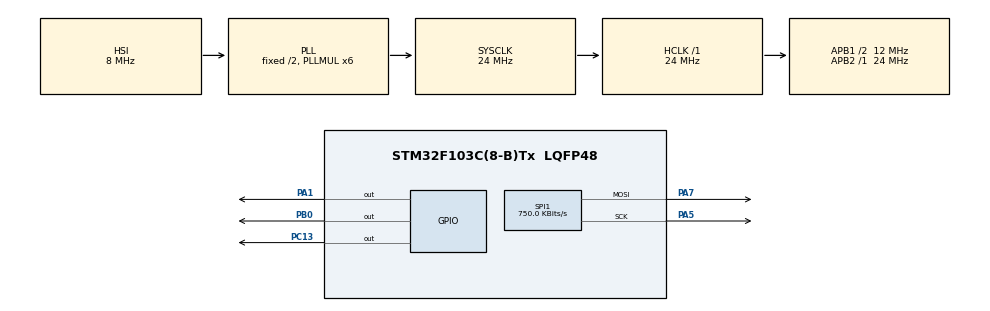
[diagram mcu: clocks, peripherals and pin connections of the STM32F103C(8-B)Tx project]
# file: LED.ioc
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Mcu.Family=STM32F1
Mcu.Name=STM32F103C(8-B)Tx
Mcu.Package=LQFP48
NVIC.PriorityGroup=NVIC_PRIORITYGROUP_4
PA1.GPIO_PuPd=GPIO_PULLUP
PA1.Signal=GPIO_Output
PA13.Mode=Serial_Wire
PA13.Signal=SYS_JTMS-SWDIO
PA14.Mode=Serial_Wire
PA14.Signal=SYS_JTCK-SWCLK
PA5.Mode=TX_Only_Simplex_Unidirect_Master
PA5.Signal=SPI1_SCK
PA7.Mode=TX_Only_Simplex_Unidirect_Master
PA7.Signal=SPI1_MOSI
PB0.Signal=GPIO_Output
PC13-TAMPER-RTC.Signal=GPIO_Output
PD0-OSC_IN.Mode=HSE-External-Oscillator
PD0-OSC_IN.Signal=RCC_OSC_IN
PD1-OSC_OUT.Mode=HSE-External-Oscillator
PD1-OSC_OUT.Signal=RCC_OSC_OUT
ProjectManager.HeapSize=0x200
ProjectManager.StackSize=0x400
ProjectManager.TargetToolchain=MDK-ARM V5.32
RCC.AHBFreq_Value=24000000
RCC.APB1CLKDivider=RCC_HCLK_DIV2
RCC.APB1Freq_Value=12000000
RCC.APB1TimFreq_Value=24000000
RCC.APB2Freq_Value=24000000
RCC.APB2TimFreq_Value=24000000
RCC.HCLKFreq_Value=24000000
RCC.PLLMUL=RCC_PLL_MUL6
RCC.SYSCLKFreq_VALUE=24000000
RCC.SYSCLKSource=RCC_SYSCLKSOURCE_PLLCLK
RCC.USBFreq_Value=24000000
SPI1.BaudRatePrescaler=SPI_BAUDRATEPRESCALER_32
SPI1.CalculateBaudRate=750.0 KBits/s
SPI1.Direction=SPI_DIRECTION_2LINES
SPI1.Mode=SPI_MODE_MASTER
SPI1.VirtualType=VM_MASTER
board=custom

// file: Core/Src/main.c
/* USER CODE BEGIN Header */
/**
  ******************************************************************************
  * @file           : main.c
  * @brief          : Main program body
  ******************************************************************************
  * @attention
  *
  * Copyright (c) 2026 STMicroelectronics.
  * All rights reserved.
  *
  * This software is licensed under terms that can be found in the LICENSE file
  * in the root directory of this software component.
  * If no LICENSE file comes with this software, it is provided AS-IS.
  *
  ******************************************************************************
  */
/* USER CODE END Header */
#include "main.h"

SPI_HandleTypeDef hspi1;

void SystemClock_Config(void);
static void MX_GPIO_Init(void);
static void MX_SPI1_Init(void);

/* USER CODE BEGIN 0 */
void writeDataSPI(uint8_t data)
{
	HAL_GPIO_WritePin(GPIOB, GPIO_PIN_0,0);
	HAL_SPI_Transmit(&hspi1, &data,1,1000);
	HAL_GPIO_WritePin(GPIOB, GPIO_PIN_0,1);
}
/* USER CODE END 0 */

int main(void)
{

  /* MCU Configuration--------------------------------------------------------*/

  /* Reset of all peripherals, Initializes the Flash interface and the Systick. */
  HAL_Init();

  /* Configure the system clock */
  SystemClock_Config();

  /* USER CODE BEGIN SysInit */
  // Test
  /* USER CODE END SysInit */

  /* Initialize all configured peripherals */
  MX_GPIO_Init();
  MX_SPI1_Init();
  /* USER CODE BEGIN 2 */
// 1. T?t LED tru?c khi b?t d?u (Gi? s? PC13, m?c cao l� t?t)
//HAL_GPIO_WritePin(GPIOC, GPIO_PIN_13, GPIO_PIN_SET);
//HAL_Delay(500);

// 2. Ki?m tra xem MPU c� t?n t?i tr�n chip n�y kh�ng
//if (MPU_TYPE == 0) {
//    // N?u chip kh�ng c� MPU, LED s? s�ng m�i d? b�o l?i
//    HAL_GPIO_WritePin(GPIOC, GPIO_PIN_13, GPIO_PIN_RESET);
//}

// 3. Kh?i t?o MPU b?o v? m?ng
//MPU_Init_ReadOnly_Example((uint32_t)my_secret_data);

//// 4. L?nh ghi "CU?NG �P" (D�ng volatile d? tr�nh b? t?i uu h�a)
//*(volatile uint8_t *)&my_secret_data[10] = 0xFF;

//// 5. Ki?m tra k?t qu?:
//// N?u code ch?y du?c xu?ng �?N ��Y, nghia l� MPU d� TH?T B?I.
//// Ch�ng ta cho LED s�ng d?ng y�n d? b�o hi?u MPU kh�ng ch?n du?c.
//if (my_secret_data[10] == 0xFF) {
//    HAL_GPIO_WritePin(GPIOC, GPIO_PIN_13, GPIO_PIN_RESET);
//}
  /* USER CODE END 2 */

  /* Infinite loop */
  /* USER CODE BEGIN WHILE */
// 	HAL_GPIO_WritePin(GPIOB, GPIO_PIN_0,1);
// 	int s = 100 ;
//   while (1)
//   {
//     /* USER CODE END WHILE */

//     /* USER CODE BEGIN 3 */
// //		HAL_GPIO_TogglePin(GPIOC,GPIO_PIN_13);
// //		HAL_GPIO_TogglePin(GPIOA,GPIO_PIN_1);
// //		HAL_Delay(s);
// 		writeDataSPI(0xFF);
// 		HAL_Delay(500);
//   }
  /* USER CODE END 3 */
}

void SystemClock_Config(void)
{
  RCC_OscInitTypeDef RCC_OscInitStruct = {0};
  RCC_ClkInitTypeDef RCC_ClkInitStruct = {0};

  /** Initializes the RCC Oscillators according to the specified parameters
  * in the RCC_OscInitTypeDef structure.
  */
  RCC_OscInitStruct.OscillatorType = RCC_OSCILLATORTYPE_HSI;
  RCC_OscInitStruct.HSIState = RCC_HSI_ON;
  RCC_OscInitStruct.HSICalibrationValue = RCC_HSICALIBRATION_DEFAULT;
  RCC_OscInitStruct.PLL.PLLState = RCC_PLL_ON;
  RCC_OscInitStruct.PLL.PLLSource = RCC_PLLSOURCE_HSI_DIV2;
  RCC_OscInitStruct.PLL.PLLMUL = RCC_PLL_MUL6;
  if (HAL_RCC_OscConfig(&RCC_OscInitStruct) != HAL_OK)
  {
    Error_Handler();
  }

  /** Initializes the CPU, AHB and APB buses clocks
  */
  RCC_ClkInitStruct.ClockType = RCC_CLOCKTYPE_HCLK|RCC_CLOCKTYPE_SYSCLK
                              |RCC_CLOCKTYPE_PCLK1|RCC_CLOCKTYPE_PCLK2;
  RCC_ClkInitStruct.SYSCLKSource = RCC_SYSCLKSOURCE_PLLCLK;
  RCC_ClkInitStruct.AHBCLKDivider = RCC_SYSCLK_DIV1;
  RCC_ClkInitStruct.APB1CLKDivider = RCC_HCLK_DIV2;
  RCC_ClkInitStruct.APB2CLKDivider = RCC_HCLK_DIV1;

  if (HAL_RCC_ClockConfig(&RCC_ClkInitStruct, FLASH_LATENCY_0) != HAL_OK)
  {
    Error_Handler();
  }
}

static void MX_SPI1_Init(void)
{

  /* SPI1 parameter configuration*/
  hspi1.Instance = SPI1;
  hspi1.Init.Mode = SPI_MODE_MASTER;
  hspi1.Init.Direction = SPI_DIRECTION_2LINES;
  hspi1.Init.DataSize = SPI_DATASIZE_8BIT;
  hspi1.Init.CLKPolarity = SPI_POLARITY_LOW;
  hspi1.Init.CLKPhase = SPI_PHASE_1EDGE;
  hspi1.Init.NSS = SPI_NSS_SOFT;
  hspi1.Init.BaudRatePrescaler = SPI_BAUDRATEPRESCALER_32;
  hspi1.Init.FirstBit = SPI_FIRSTBIT_MSB;
  hspi1.Init.TIMode = SPI_TIMODE_DISABLE;
  hspi1.Init.CRCCalculation = SPI_CRCCALCULATION_DISABLE;
  hspi1.Init.CRCPolynomial = 10;
  if (HAL_SPI_Init(&hspi1) != HAL_OK)
  {
    Error_Handler();
  }

}

static void MX_GPIO_Init(void)
{
  GPIO_InitTypeDef GPIO_InitStruct = {0};

  /* GPIO Ports Clock Enable */
  __HAL_RCC_GPIOC_CLK_ENABLE();
  __HAL_RCC_GPIOD_CLK_ENABLE();
  __HAL_RCC_GPIOA_CLK_ENABLE();
  __HAL_RCC_GPIOB_CLK_ENABLE();

  /*Configure GPIO pin Output Level */
  HAL_GPIO_WritePin(GPIOC, GPIO_PIN_13, GPIO_PIN_RESET);

  /*Configure GPIO pin Output Level */
  HAL_GPIO_WritePin(GPIOA, GPIO_PIN_1, GPIO_PIN_RESET);

  /*Configure GPIO pin Output Level */
  HAL_GPIO_WritePin(GPIOB, GPIO_PIN_0, GPIO_PIN_RESET);

  /*Configure GPIO pin : PC13 */
  GPIO_InitStruct.Pin = GPIO_PIN_13;
  GPIO_InitStruct.Mode = GPIO_MODE_OUTPUT_PP;
  GPIO_InitStruct.Pull = GPIO_NOPULL;
  GPIO_InitStruct.Speed = GPIO_SPEED_FREQ_LOW;
  HAL_GPIO_Init(GPIOC, &GPIO_InitStruct);

  /*Configure GPIO pin : PA1 */
  GPIO_InitStruct.Pin = GPIO_PIN_1;
  GPIO_InitStruct.Mode = GPIO_MODE_OUTPUT_PP;
  GPIO_InitStruct.Pull = GPIO_PULLUP;
  GPIO_InitStruct.Speed = GPIO_SPEED_FREQ_LOW;
  HAL_GPIO_Init(GPIOA, &GPIO_InitStruct);

  /*Configure GPIO pin : PB0 */
  GPIO_InitStruct.Pin = GPIO_PIN_0;
  GPIO_InitStruct.Mode = GPIO_MODE_OUTPUT_PP;
  GPIO_InitStruct.Pull = GPIO_NOPULL;
  GPIO_InitStruct.Speed = GPIO_SPEED_FREQ_LOW;
  HAL_GPIO_Init(GPIOB, &GPIO_InitStruct);

}

void Error_Handler(void)
{
  __disable_irq();
  while (1)
  {
  }
}
